# R7FA4W1AD register map
Vendor: Renesas; Series: RA4; File version: 1.0
CPU: CM4 r0p1, little endian, MPU, FPU, VTOR, 4 interrupt priority bits
Registers are 8-bit, read-write, reset 0x0 unless marked. A register's access mark holds for its fields unless they carry their own. Offsets are from the block's base; [hi:lo] are bit positions; {n}, {i} and the like mark numbered series; 'fields as' and 'values as' point back to an identical list.

## USBFS — USB 2.0 FS Module
Base 0x40090000
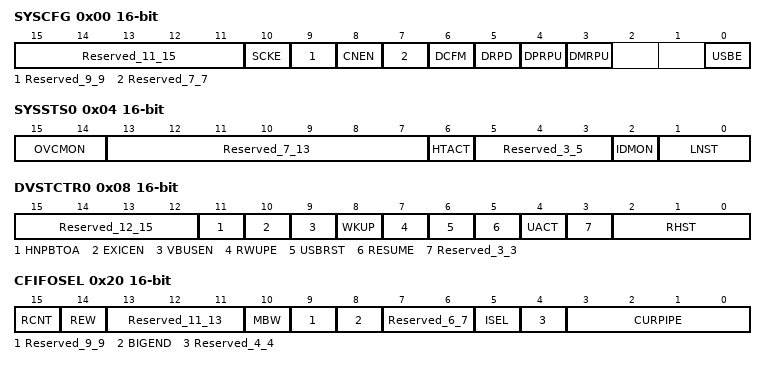
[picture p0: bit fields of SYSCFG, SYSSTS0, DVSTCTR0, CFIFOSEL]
0x00 SYSCFG 16-bit — System Configuration Control Register
  [15:11] Reserved_11_15 — These bits are read as 00000. The write value should be 00000.
  [10] SCKE — USB Clock Enable
  [9] Reserved_9_9 — This bit is read as 0. The write value should be 0.
  [8] CNEN — CNEN Single End Receiver Enable
  [7] Reserved_7_7 — This bit is read as 0. The write value should be 0.
  [6] DCFM — Controller Function Select
  [5] DRPD — D+/D- Line Resistor Control
  [4] DPRPU — D+ Line Resistor Control
  [3] DMRPU — D- Line Resistor Control
  [0] USBE — USB Operation Enable
0x04 SYSSTS0 16-bit ro reset not defined — System Configuration Status Register 0
  [15:14] OVCMON — External USB0_OVRCURA/ USB0_OVRCURB Input Pin MonitorThe OCVMON[1] bit indicates the status of the USBHS_OVRCURA pin. The OCVMON[0] bit indicates the status of the USBHS_OVRCURB pin.
  [13:7] Reserved_7_13 — These bits are read as 0000000.
  [6] HTACT — USB Host Sequencer Status Monitor
  [5:3] Reserved_3_5 — These bits are read as 000.
  [2] IDMON — External ID0 Input Pin Monitor
  [1:0] LNST — USB Data Line Status Monitor
0x08 DVSTCTR0 16-bit — Device State Control Register 0
  [15:12] Reserved_12_15 — These bits are read as 0000. The write value should be 0000.
  [11] HNPBTOA — Host Negotiation Protocol (HNP) Control This bit is used when switching from device B to device A while in OTG mode. If the HNPBTOA bit is 1, the internal function control keeps the suspended state until the HNP processing ends even though SYSCFG.DPRPU = 0 or SYSCFG.DCFM = 1 is set.
  [10] EXICEN — USB_EXICEN Output Pin Control
  [9] VBUSEN — USB_VBUSEN Output Pin Control
  [8] WKUP — Wakeup Output
  [7] RWUPE — Wakeup Detection Enable
  [6] USBRST — USB Bus Reset Output
  [5] RESUME — Resume Output
  [4] UACT — USB Bus Enable
  [3] Reserved_3_3 — This bit is read as 0. The write value should be 0.
  [2:0] RHST ro — USB Bus Reset Status
0x14 CFIFO 16-bit — CFIFO Port Register
  [15:0] FIFOPORT — FIFO PortRead receive data from the FIFO buffer or write transmit data to the FIFO buffer by accessing these bits.
0x14 CFIFOL (alternate view of CFIFO) — CFIFO Port Register L
0x18 D0FIFO 16-bit — D0FIFO Port Register
  fields as CFIFO
0x18 D0FIFOL (alternate view of D0FIFO) — D0FIFO Port Register L
0x1C D1FIFO 16-bit — D1FIFO Port Register
  fields as CFIFO
0x1C D1FIFOL (alternate view of D1FIFO) — D1FIFO Port Register L
0x20 CFIFOSEL 16-bit — CFIFO Port Select Register
  [15] RCNT — Read Count Mode
  [14] REW — Buffer Pointer Rewind
  [13:11] Reserved_11_13 — These bits are read as 000. The write value should be 000.
  [10] MBW — CFIFO Port Access Bit Width
  [9] Reserved_9_9 — This bit is read as 0. The write value should be 0.
  [8] BIGEND — CFIFO Port Endian Control
  [7:6] Reserved_6_7 — These bits are read as 00. The write value should be 00.
  [5] ISEL — CFIFO Port Access Direction When DCP is Selected
  [4] Reserved_4_4 — This bit is read as 0. The write value should be 0.
  [3:0] CURPIPE — CFIFO Port Access Pipe Specification
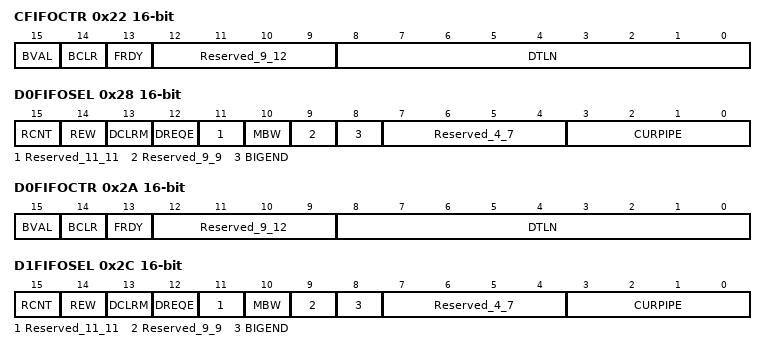
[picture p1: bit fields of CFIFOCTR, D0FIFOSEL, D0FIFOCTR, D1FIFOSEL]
0x22 CFIFOCTR 16-bit — CFIFO Port Control Register
  [15] BVAL — Buffer Memory Valid Flag
  [14] BCLR — CPU Buffer ClearNote: Only 0 can be read.
  [13] FRDY ro — FIFO Port Ready
  [12:9] Reserved_9_12 — These bits are read as 0000. The write value should be 0000.
  [8:0] DTLN ro — Receive Data LengthIndicates the length of the receive data.
0x28 D0FIFOSEL 16-bit — D0FIFO Port Select Register
  [15] RCNT — Read Count Mode
  [14] REW — Buffer Pointer RewindNote: Only 0 can be read.
  [13] DCLRM — Auto Buffer Memory Clear Mode Accessed after Specified Pipe Data is Read
  [12] DREQE — DMA/DTC Transfer Request Enable
  [11] Reserved_11_11 — This bit is read as 0. The write value should be 0.
  [10] MBW — FIFO Port Access Bit Width
  [9] Reserved_9_9 — This bit is read as 0. The write value should be 0.
  [8] BIGEND — FIFO Port Endian Control
  [7:4] Reserved_4_7 — These bits are read as 0000. The write value should be 0000.
  [3:0] CURPIPE — FIFO Port Access Pipe Specification
0x2A D0FIFOCTR 16-bit — D0FIFO Port Control Register
  fields as CFIFOCTR
0x2C D1FIFOSEL 16-bit — D1FIFO Port Select Register
  [15] RCNT — Read Count Mode
  [14] REW — Buffer Pointer Rewind
  [13] DCLRM — Auto Buffer Memory Clear Mode Accessed after Specified Pipe Data is Read
  [12] DREQE — DMA/DTC Transfer Request Enable
  [11] Reserved_11_11 — This bit is read as 0. The write value should be 0.
  [10] MBW — FIFO Port Access Bit Width
  [9] Reserved_9_9 — This bit is read as 0. The write value should be 0.
  [8] BIGEND — FIFO Port Endian Control
  [7:4] Reserved_4_7 — These bits are read as 0000. The write value should be 0000.
  [3:0] CURPIPE — FIFO Port Access Pipe Specification
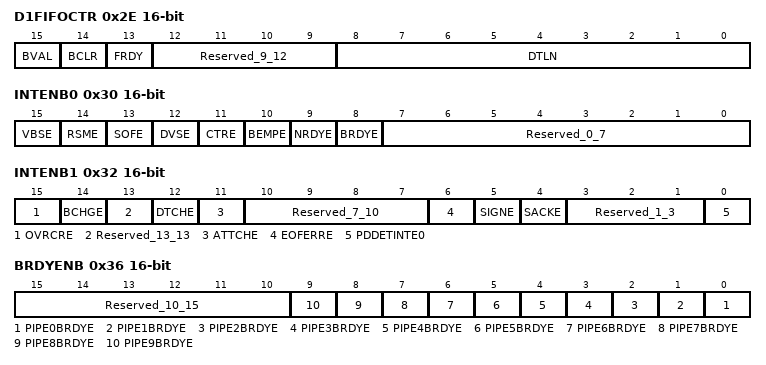
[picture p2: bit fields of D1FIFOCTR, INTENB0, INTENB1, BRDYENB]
0x2E D1FIFOCTR 16-bit — D1FIFO Port Control Register
  fields as CFIFOCTR
0x30 INTENB0 16-bit — Interrupt Enable Register 0
  [15] VBSE — VBUS Interrupt Enable
  [14] RSME — Resume Interrupt Enable
  [13] SOFE — Frame Number Update Interrupt Enable
  [12] DVSE — Device State Transition Interrupt Enable
  [11] CTRE — Control Transfer Stage Transition Interrupt Enable
  [10] BEMPE — Buffer Empty Interrupt Enable
  [9] NRDYE — Buffer Not Ready Response Interrupt Enable
  [8] BRDYE — Buffer Ready Interrupt Enable
  [7:0] Reserved_0_7 — These bits are read as 00000000. The write value should be 00000000.
0x32 INTENB1 16-bit — Interrupt Enable Register 1
  [15] OVRCRE — Overcurrent Input Change Interrupt Enable
  [14] BCHGE — USB Bus Change Interrupt Enable
  [13] Reserved_13_13 — This bit is read as 0. The write value should be 0.
  [12] DTCHE — Disconnection Detection Interrupt Enable
  [11] ATTCHE — Connection Detection Interrupt Enable
  [10:7] Reserved_7_10 — These bits are read as 0000. The write value should be 0000.
  [6] EOFERRE — EOF Error Detection Interrupt Enable
  [5] SIGNE — Setup Transaction Error Interrupt Enable
  [4] SACKE — Setup Transaction Normal Response Interrupt Enable
  [3:1] Reserved_1_3 — These bits are read as 000. The write value should be 000.
  [0] PDDETINTE0 — PDDETINT0 Detection Interrupt Enable
0x36 BRDYENB 16-bit — BRDY Interrupt Enable Register
  [15:10] Reserved_10_15 — These bits are read as 000000. The write value should be 000000.
  [n] PIPE{n}BRDYE (n=0..9) — BRDY Interrupt Enable for PIPE{n}
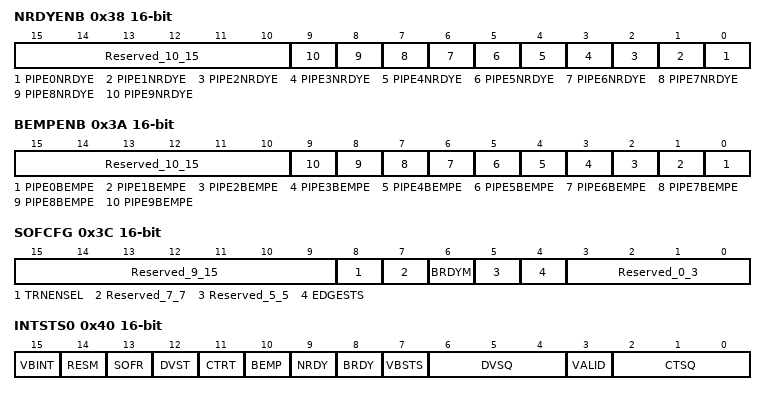
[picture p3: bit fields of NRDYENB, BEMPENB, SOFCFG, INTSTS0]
0x38 NRDYENB 16-bit — NRDY Interrupt Enable Register
  [15:10] Reserved_10_15 — These bits are read as 000000. The write value should be 000000.
  [n] PIPE{n}NRDYE (n=0..9) — NRDY Interrupt Enable for PIPE{n}
0x3A BEMPENB 16-bit — BEMP Interrupt Enable Register
  [15:10] Reserved_10_15 — These bits are read as 000000. The write value should be 000000.
  [n] PIPE{n}BEMPE (n=0..9) — BEMP Interrupt Enable for PIPE{n}
0x3C SOFCFG 16-bit — SOF Output Configuration Register
  [15:9] Reserved_9_15 — These bits are read as 0000000. The write value should be 0000000.
  [8] TRNENSEL — Transaction,Enabled Time Select
  [7] Reserved_7_7 — This bit is read as 0. The write value should be 0.
  [6] BRDYM — BRDY Interrupt Status Clear Timing
  [5] Reserved_5_5 — This bit is read as 0. The write value should be 0.
  [4] EDGESTS ro — Edge Interrupt Output Status Monitor
  [3:0] Reserved_0_3 — These bits are read as 0000. The write value should be 0000.
0x40 INTSTS0 16-bit (reset mask 0xFF7F) — Interrupt Status Register 0
  [15] VBINT write-0-clears read-modifies — VBUS Interrupt Status
  [14] RESM write-0-clears read-modifies — Resume Interrupt Status
  [13] SOFR write-0-clears read-modifies — Frame Number Refresh Interrupt Status
  [12] DVST write-0-clears read-modifies — Device State Transition Interrupt Status
  [11] CTRT write-0-clears read-modifies — Control Transfer Stage Transition Interrupt Status
  [10] BEMP ro — Buffer Empty Interrupt Status
  [9] NRDY ro — Buffer Not Ready Interrupt Status
  [8] BRDY ro — Buffer Ready Interrupt Status
  [7] VBSTS ro — VBUS Input Status
  [6:4] DVSQ ro — Device State
  [3] VALID — USB Request Reception
  [2:0] CTSQ ro — Control Transfer Stage
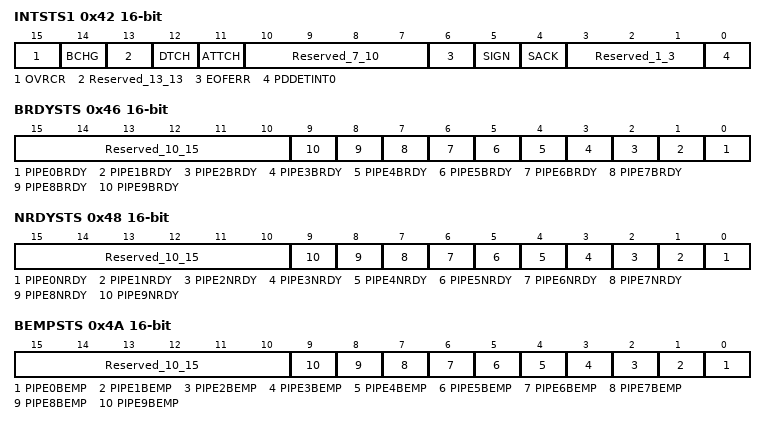
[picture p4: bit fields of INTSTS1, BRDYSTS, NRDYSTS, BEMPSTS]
0x42 INTSTS1 16-bit — Interrupt Status Register 1
  [15] OVRCR write-0-clears read-modifies — Overcurrent Input Change Interrupt Status
  [14] BCHG write-0-clears read-modifies — USB Bus Change Interrupt Status
  [13] Reserved_13_13 — This bit is read as 0. The write value should be 0.
  [12] DTCH write-0-clears read-modifies — USB Disconnection Detection Interrupt Status
  [11] ATTCH write-0-clears read-modifies — ATTCH Interrupt Status
  [10:7] Reserved_7_10 — These bits are read as 0000. The write value should be 0000.
  [6] EOFERR write-0-clears read-modifies — EOF Error Detection Interrupt Status
  [5] SIGN write-0-clears read-modifies — Setup Transaction Error Interrupt Status
  [4] SACK write-0-clears read-modifies — Setup Transaction Normal Response Interrupt Status
  [3:1] Reserved_1_3 — These bits are read as 000. The write value should be 000.
  [0] PDDETINT0 write-0-clears read-modifies — PDDET0 Detection Interrupt Status
0x46 BRDYSTS 16-bit — BRDY Interrupt Status Register
  [15:10] Reserved_10_15 — These bits are read as 000000. The write value should be 000000.
  [n] PIPE{n}BRDY write-0-clears read-modifies (n=0..9) — BRDY Interrupt Status for PIPE{n}
0x48 NRDYSTS 16-bit — NRDY Interrupt Status Register
  [15:10] Reserved_10_15 — These bits are read as 000000. The write value should be 000000.
  [n] PIPE{n}NRDY write-0-clears read-modifies (n=0..9) — NRDY Interrupt Status for PIPE{n}
0x4A BEMPSTS 16-bit — BEMP Interrupt Status Register
  [15:10] Reserved_10_15 — These bits are read as 000000. The write value should be 000000.
  [n] PIPE{n}BEMP write-0-clears read-modifies (n=0..9) — BEMP Interrupt Status for PIPE{n}
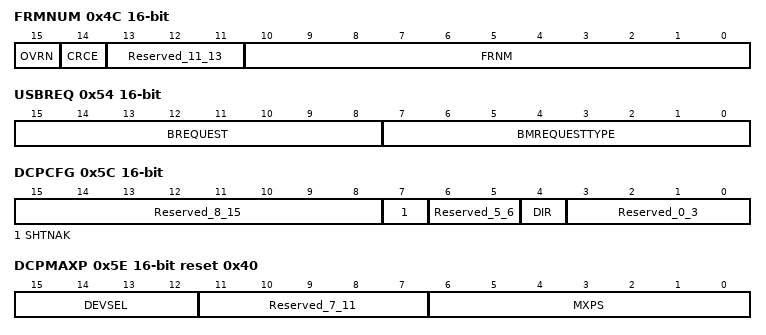
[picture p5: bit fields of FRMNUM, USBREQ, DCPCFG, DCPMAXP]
0x4C FRMNUM 16-bit — Frame Number Register
  [15] OVRN — Overrun/Underrun Detection Status
  [14] CRCE — Receive Data Error
  [13:11] Reserved_11_13 — These bits are read as 000. The write value should be 000.
  [10:0] FRNM ro — Frame NumberLatest frame number
0x54 USBREQ 16-bit — USB Request Type Register
  [15:8] BREQUEST — RequestThese bits store the USB request bRequest value.
  [7:0] BMREQUESTTYPE — Request TypeThese bits store the USB request bmRequestType value.
0x56 USBVAL 16-bit — USB Request Value Register
  [15:0] WVALUE — ValueThese bits store the USB request Value value.
0x58 USBINDX 16-bit — USB Request Index Register
  [15:0] WINDEX — IndexThese bits store the USB request wIndex value.
0x5A USBLENG 16-bit — USB Request Length Register
  [15:0] WLENGTH — LengthThese bits store the USB request wLength value.
0x5C DCPCFG 16-bit — DCP Configuration Register
  [15:8] Reserved_8_15 — These bits are read as 00000000. The write value should be 00000000.
  [7] SHTNAK — Pipe Disabled at End of Transfer
  [6:5] Reserved_5_6 — These bits are read as 00. The write value should be 00.
  [4] DIR — Transfer Direction
  [3:0] Reserved_0_3 — These bits are read as 0000. The write value should be 0000.
0x5E DCPMAXP 16-bit reset 0x40 — DCP Maximum Packet Size Register
  [15:12] DEVSEL — Device Select
  [11:7] Reserved_7_11 — These bits are read as 00000. The write value should be 00000.
  [6:0] MXPS — Maximum Packet SizeThese bits set the maximum amount of data (maximum packet size) in payloads for the DCP.
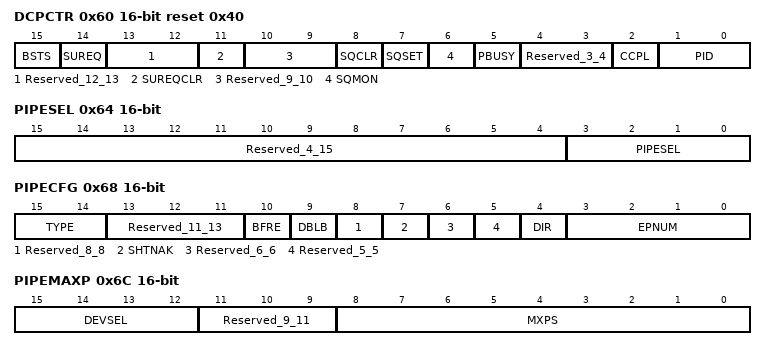
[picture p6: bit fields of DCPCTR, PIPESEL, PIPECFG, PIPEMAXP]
0x60 DCPCTR 16-bit reset 0x40 — DCP Control Register
  [15] BSTS ro — Buffer Status
  [14] SUREQ — Setup Token Transmission
  [13:12] Reserved_12_13 — These bits are read as 00. The write value should be 00.
  [11] SUREQCLR — SUREQ Bit Clear
  [10:9] Reserved_9_10 — These bits are read as 00. The write value should be 00.
  [8] SQCLR — Sequence Toggle Bit Clear
  [7] SQSET — Sequence Toggle Bit Set
  [6] SQMON ro — Sequence Toggle Bit Monitor
  [5] PBUSY ro — Pipe Busy
  [4:3] Reserved_3_4 — These bits are read as 00. The write value should be 00.
  [2] CCPL — Control Transfer End Enable
  [1:0] PID — Response PID
0x64 PIPESEL 16-bit — Pipe Window Select Register
  [15:4] Reserved_4_15 — These bits are read as 000000000000. The write value should be 000000000000.
  [3:0] PIPESEL — Pipe Window Select
0x68 PIPECFG 16-bit — Pipe Configuration Register
  [15:14] TYPE — Transfer Type
  [13:11] Reserved_11_13 — These bits are read as 000. The write value should be 000.
  [10] BFRE — BRDY Interrupt Operation Specification
  [9] DBLB — Double Buffer Mode
  [8] Reserved_8_8 — This bit is read as 0. The write value should be 0.
  [7] SHTNAK — Pipe Disabled at End of Transfer
  [6] Reserved_6_6 — This bit is read as 0. The write value should be 0.
  [5] Reserved_5_5 — This bit is read as 0. The write value should be 0.
  [4] DIR — Transfer Direction
  [3:0] EPNUM — Endpoint NumberThese bits specify the endpoint number for the selected pipe.Setting 0000b means unused pipe.
0x6C PIPEMAXP 16-bit (reset mask 0xFFBF) — Pipe Maximum Packet Size Register
  [15:12] DEVSEL — Device Select
  [11:9] Reserved_9_11 — These bits are read as 000. The write value should be 000.
  [8:0] MXPS — Maximum Packet SizePIPE1 and PIPE2: 1 byte (001h) to 256 bytes (100h)PIPE3 to PIPE5: 8 bytes (008h), 16 bytes (010h), 32 bytes (020h), 64 bytes (040h) (Bits [8:7] and [2:0] are not provided.)PIPE6 to PIPE9: 1 byte (001h) to 64 bytes (040h) (Bits [8:7] are not provided.)
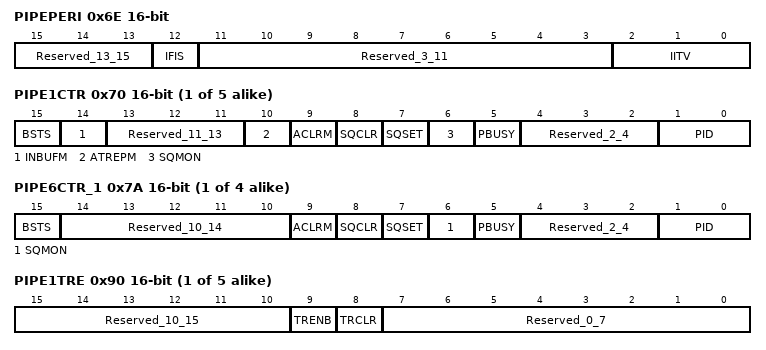
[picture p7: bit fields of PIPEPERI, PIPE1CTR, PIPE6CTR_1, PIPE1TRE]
0x6E PIPEPERI 16-bit — Pipe Cycle Control Register
  [15:13] Reserved_13_15 — These bits are read as 000. The write value should be 000.
  [12] IFIS — Isochronous IN Buffer Flush
  [11:3] Reserved_3_11 — These bits are read as 000000000. The write value should be 000000000.
  [2:0] IITV — Interval Error Detection IntervalSpecifies the interval error detection timing for the selected pipe in terms of frames, which is expressed as nth power of 2.
{0x6E+2i} PIPE{i}CTR (i=1..5) 16-bit — Pipe {i} Control Register
  [15] BSTS ro — Buffer Status
  [14] INBUFM ro — Transmit Buffer Monitor
  [13:11] Reserved_11_13 — These bits are read as 000. The write value should be 000.
  [10] ATREPM — Auto Response Mode
  [9] ACLRM — Auto Buffer Clear Mode
  [8] SQCLR — Sequence Toggle Bit Clear
  [7] SQSET — Sequence Toggle Bit Set
  [6] SQMON ro — Sequence Toggle Bit Confirmation
  [5] PBUSY ro — Pipe Busy
  [4:2] Reserved_2_4 — These bits are read as 000. The write value should be 000.
  [1:0] PID — Response PID
{0x6E+2i} PIPE{i}CTR_1 (i=6..9) 16-bit — Pipe {i} Control Register
  [15] BSTS ro — Buffer Status
  [14:10] Reserved_10_14 — These bits are read as 00000. The write value should be 00000.
  [9] ACLRM — Auto Buffer Clear Mode
  [8] SQCLR wo — Sequence Toggle Bit Clear
  [7] SQSET wo — Sequence Toggle Bit Set
  [6] SQMON ro — Sequence Toggle Bit Confirmation
  [5] PBUSY ro — Pipe Busy
  [4:2] Reserved_2_4 — These bits are read as 000. The write value should be 000.
  [1:0] PID — Response PID
{0x8C+4i} PIPE{i}TRE (i=1..5) 16-bit — Pipe {i} Transaction Counter Enable Register
  [15:10] Reserved_10_15 — These bits are read as 000000. The write value should be 000000.
  [9] TRENB — Transaction Counter Enable
  [8] TRCLR — Transaction Counter Clear
  [7:0] Reserved_0_7 — These bits are read as 00000000. The write value should be 00000000.
{0x8E+4i} PIPE{i}TRN (i=1..5) 16-bit — Pipe {i} Transaction Counter Register
  [15:0] TRNCNT — Transaction Counter
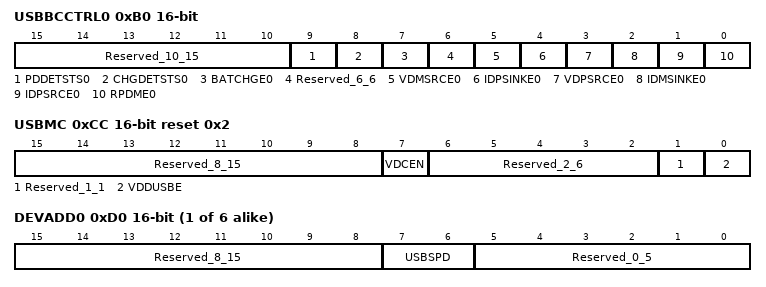
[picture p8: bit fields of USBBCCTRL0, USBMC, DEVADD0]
0xB0 USBBCCTRL0 16-bit — BC Control Register 0
  [15:10] Reserved_10_15 — These bits are read as 000000. The write value should be 000000.
  [9] PDDETSTS0 ro — D+ Pin 0.6 V Input Detection Status
  [8] CHGDETSTS0 ro — D- Pin 0.6 V Input Detection Status
  [7] BATCHGE0 — BC (Battery Charger) Function Ch0 General Enable Control
  [6] Reserved_6_6 — This bit is read as 0. The write value should be 0.
  [5] VDMSRCE0 — D- Pin VDMSRC (0.6 V) Output Control
  [4] IDPSINKE0 — D+ Pin 0.6 V Input Detection (Comparator and Sink) Control
  [3] VDPSRCE0 — D+ Pin VDPSRC (0.6 V) Output Control
  [2] IDMSINKE0 — D- Pin 0.6 V Input Detection (Comparator and Sink) Control
  [1] IDPSRCE0 — D+ Pin IDPSRC Output Control
  [0] RPDME0 — D- Pin Pull,Down Control
0xCC USBMC 16-bit reset 0x2 — USB Module Control Register
  [15:8] Reserved_8_15 — These bits are read as 00000000. The write value should be 00000000.
  [7] VDCEN — USB Regulator On/Off Control
  [6:2] Reserved_2_6 — These bits are read as 00000. The write value should be 00000.
  [1] Reserved_1_1 — This bit is read as 1. The write value should be 1.
  [0] VDDUSBE — USB Reference Power Supply Circuit On/Off Control
{0xD0+2i} DEVADD{i} (i=0..5) 16-bit — Device Address {i} Configuration Register
  [15:8] Reserved_8_15 — These bits are read as 00000000. The write value should be 00000000.
  [7:6] USBSPD — Transfer Speed of Communication Target Device
  [5:0] Reserved_0_5 — These bits are read as 000000. The write value should be 000000.
